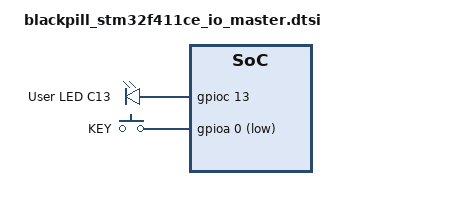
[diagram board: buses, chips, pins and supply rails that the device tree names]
/ {
	inputs_outputs: io {

		/* System state module */
		system_state_module {
			leds {
				compatible = "gpio-leds";
				led_indicator: led_0 {
					gpios = <&gpioc 13 GPIO_ACTIVE_HIGH>;
					label = "User LED C13";
				};
			};
		};

		button_module {
			btns {
				compatible = "gpio-keys";
				button0: button_0 {
					gpios = <&gpioa 0 GPIO_ACTIVE_LOW>;
					label = "KEY";
				};
			};
		};
	};
};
